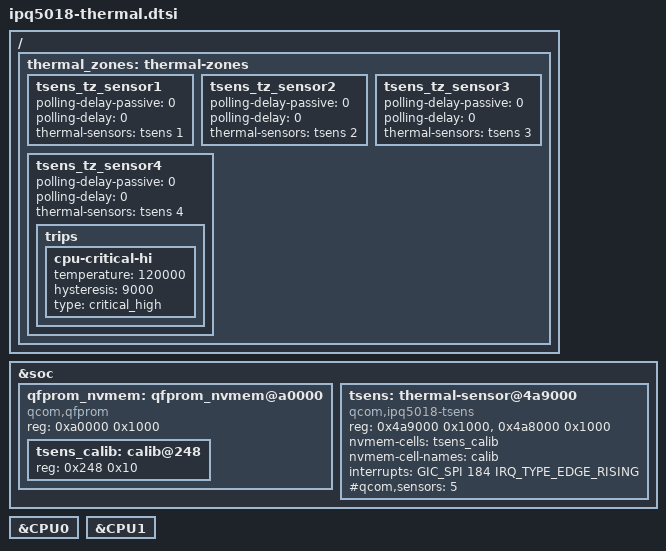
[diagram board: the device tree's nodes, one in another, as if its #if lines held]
/*
 * Copyright (c) 2017, 2020-2021 The Linux Foundation. All rights reserved.
 *
 * Permission to use, copy, modify, and/or distribute this software for any
 * purpose with or without fee is hereby granted, provided that the above
 * copyright notice and this permission notice appear in all copies.
 *
 * THE SOFTWARE IS PROVIDED "AS IS" AND THE AUTHOR DISCLAIMS ALL WARRANTIES
 * WITH REGARD TO THIS SOFTWARE INCLUDING ALL IMPLIED WARRANTIES OF
 * MERCHANTABILITY AND FITNESS. IN NO EVENT SHALL THE AUTHOR BE LIABLE FOR
 * ANY SPECIAL, DIRECT, INDIRECT, OR CONSEQUENTIAL DAMAGES OR ANY DAMAGES
 * WHATSOEVER RESULTING FROM LOSS OF USE, DATA OR PROFITS, WHETHER IN AN
 * ACTION OF CONTRACT, NEGLIGENCE OR OTHER TORTIOUS ACTION, ARISING OUT OF
 * OR IN CONNECTION WITH THE USE OR PERFORMANCE OF THIS SOFTWARE.
 */

/ {
	thermal_zones: thermal-zones {
		tsens_tz_sensor1 {
			polling-delay-passive = <0>;
			polling-delay = <0>;
			thermal-sensors = <&tsens 1>;

			trips {
				cpu-critical-hi {
					temperature = <120000>;
					hysteresis = <2>;
					type = "critical_high";
				};

				cpu-config-hi {
					temperature = <100000>;
					hysteresis = <2>;
					type = "configurable_hi";
				};

				cpu-config-lo {
					temperature = <90000>;
					hysteresis = <2>;
					type = "configurable_lo";
				};

				cpu-critical-low {
					temperature = <0>;
					hysteresis = <2>;
					type = "critical_low";
				};
			};
		};

		tsens_tz_sensor2 {
			polling-delay-passive = <0>;
			polling-delay = <0>;
			thermal-sensors = <&tsens 2>;

			trips {
				cpu-critical-hi {
					temperature = <120000>;
					hysteresis = <2>;
					type = "critical_high";
				};

				cpu-config-hi {
					temperature = <100000>;
					hysteresis = <2>;
					type = "configurable_hi";
				};

				cpu-config-lo {
					temperature = <90000>;
					hysteresis = <2>;
					type = "configurable_lo";
				};

				cpu-critical-low {
					temperature = <0>;
					hysteresis = <2>;
					type = "critical_low";
				};
			};
		};

		tsens_tz_sensor3 {
			polling-delay-passive = <0>;
			polling-delay = <0>;
			thermal-sensors = <&tsens 3>;

			trips {
				cpu-critical-hi {
					temperature = <120000>;
					hysteresis = <2>;
					type = "critical_high";
				};

				cpu-config-hi {
					temperature = <100000>;
					hysteresis = <2>;
					type = "configurable_hi";
				};

				cpu-config-lo {
					temperature = <90000>;
					hysteresis = <2>;
					type = "configurable_lo";
				};

				cpu-critical-low {
					temperature = <0>;
					hysteresis = <2>;
					type = "critical_low";
				};
			};
		};

		tsens_tz_sensor4 {
			polling-delay-passive = <0>;
			polling-delay = <0>;
			thermal-sensors = <&tsens 4>;

			trips {
				cpu-critical-hi {
					temperature = <120000>;
					hysteresis = <2>;
					type = "critical_high";
				};

				cpu-config-hi {
					temperature = <100000>;
					hysteresis = <2>;
					type = "configurable_hi";
				};

				cpu-config-lo {
					temperature = <90000>;
					hysteresis = <2>;
					type = "configurable_lo";
				};

				cpu-critical-low {
					temperature = <0>;
					hysteresis = <2>;
					type = "critical_low";
				};
			};
		};
	};
};

&soc {
	qfprom_nvmem: qfprom_nvmem@a0000 {
		#address-cells = <1>;
		#size-cells = <1>;
		compatible = "qcom,qfprom";
		reg = <0xa0000 0x1000>;
		tsens_calib: calib@248 {
			reg = <0x248 0x10>;
		};
	};

	tsens: thermal-sensor@4a9000 {
		compatible = "qcom,ipq5018-tsens";
		reg = <0x4a9000 0x1000>, /* TM */
		      <0x4a8000 0x1000>; /* SORT */
		nvmem-cells = <&tsens_calib>;
		nvmem-cell-names = "calib";
		interrupts = <GIC_SPI 184 IRQ_TYPE_EDGE_RISING>;
		#qcom,sensors = <5>;
		#thermal-sensor-cells = <1>;
	};
};

/* If CPUFreq cooling is enabled */
#if defined(__CPU_THERMAL__)

&thermal_zones {
	tsens_tz_sensor1 {
		/delete-node/ trips;
	};

	tsens_tz_sensor2 {
		/delete-node/ trips;
	};

	tsens_tz_sensor3 {
		/delete-node/ trips;
	};

	tsens_tz_sensor4 {
		/delete-node/ trips;

		/* Trips with CPUFreq cooling maps */
		trips {
			cpu-critical-hi {
				temperature = <120000>;
				hysteresis = <9000>;
				type = "critical_high";
			};
		};
	};
};

&CPU0 {
	#cooling-cells = <2>;
};

&CPU1 {
	#cooling-cells = <2>;
};
#endif
